# CAL0 register map
Vendor: Texas Instruments
Peripheral module from a debugger description file (folder am65x).
Registers are 32-bit, read-write, reset 0x0 unless marked. A register's access mark holds for its fields unless they carry their own. Offsets are as the file gives them; lines under a group give offsets from that group; [hi:lo] are bit positions; {n}, {i} and the like mark numbered series; 'fields as' and 'values as' point back to an identical list; <NAME> marks a mode.

## CAL0 (part 1 of 2)
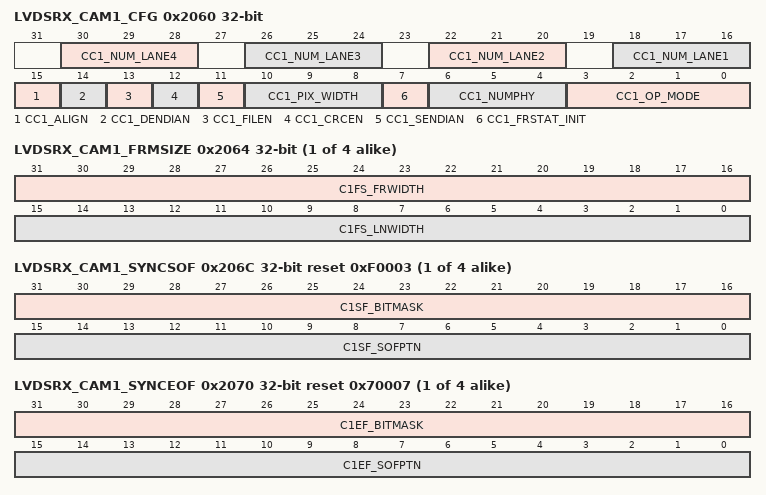
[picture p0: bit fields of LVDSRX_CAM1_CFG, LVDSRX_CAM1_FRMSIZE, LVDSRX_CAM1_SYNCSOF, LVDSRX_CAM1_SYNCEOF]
0x2060 LVDSRX_CAM1_CFG
  [30:28] CC1_NUM_LANE4 — Number of lanes of PHY4 when NUM_PHY&gt;3
  [26:24] CC1_NUM_LANE3 — Number of lanes of PHY3 when NUM_PHY&gt;2
  [22:20] CC1_NUM_LANE2 — Number of lanes of PHY2 when NUM_PHY&gt;1
  [18:16] CC1_NUM_LANE1 — Number of lanes of PHY1
  [15] CC1_ALIGN — MSB, LSB alignment for output pixel data 0: LSB align 1: MSB align
  [14] CC1_DENDIAN — Transmit format of none SYNC area 0: Little endian 1: big endian
  [13] CC1_FILEN — 1: Transmitted data includes filier codes
  [12] CC1_CRCEN — 1: enables checking of the checksum transmitted in the APTINA HiSPi data stream
  [11] CC1_SENDIAN — Transmit format of SYNC area 0: Little endian 1: big endian
  [10:8] CC1_PIX_WIDTH — Word width of recovered parallel data. 0: 8-BITS 1: 10-BITS 2: 12-BITS 3: 14-BITS 4: 16-BITS 5-7: RESERVED
  [7] CC1_FRSTAT_INIT — Specifies Initial frame state in mode2,mode4,mod5 and mode8.If the first comming sync code is knows as start of frame(SOF) when enable decoding, it is able to write 0. If sync code is unknown, should write 1.In other mode, should be coded 0.
  [6:4] CC1_NUMPHY — Number of PHYs 0 ~ 4 is available
  [3:0] CC1_OP_MODE — Protocol selection 0: Serial LVDS mode 1 1: Serial LVDS mode 2 2: Serial LVDS mode 3 3: Serial LVDS mode 4 4: Serial LVDS mode 5 5: Serial LVDS mode 6 6: Serial LVDS mode 7 7: Serial LVDS mode 8 8: Serial LVDS mode 9-15: Reserved
{0x2044+0x20*i} LVDSRX_CAM{i}_FRMSIZE (i=1..4)
  [31:16] C{i}FS_FRWIDTH — Frame size in number of image lines
  [15:0] C{i}FS_LNWIDTH — Image line width in number of data words
{0x2048+0x20*i} LVDSRX_CAM{i}_MAXWIDTH reset 0xFFFF (i=1..4)
  [15:0] C{i}MW_MAXWIDTH — The maximum line width expected in number of pixels.
{0x204C+0x20*i} LVDSRX_CAM{i}_SYNCSOF reset 0xF0003 (i=1..4)
  [31:16] C{i}SF_BITMASK — Specifies the mask bit to be compared. Example: set 0x3ff when doing pattern matching for low 10bit.
  [15:0] C{i}SF_SOFPTN — Specifies SOF(Start Of Frame) sync pattern
{0x2050+0x20*i} LVDSRX_CAM{i}_SYNCEOF reset 0x70007 (i=1..4)
  [31:16] C{i}EF_BITMASK — Specifies the mask bit to be compared. Example: set 0x3ff when doing pattern matching for low 10bit.
  [15:0] C{i}EF_SOFPTN — Specifies SOF(End Of Frame) sync pattern
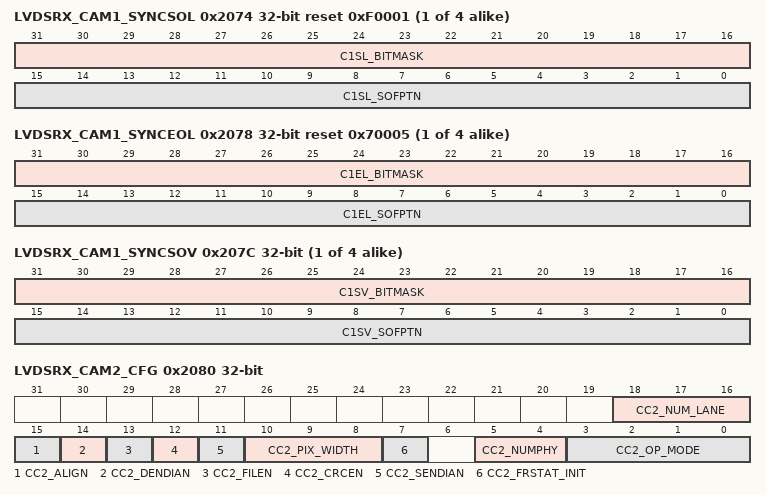
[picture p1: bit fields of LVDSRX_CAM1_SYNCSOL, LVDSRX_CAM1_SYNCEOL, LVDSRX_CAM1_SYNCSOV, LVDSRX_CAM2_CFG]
{0x2054+0x20*i} LVDSRX_CAM{i}_SYNCSOL reset 0xF0001 (i=1..4)
  [31:16] C{i}SL_BITMASK — Specifies the mask bit to be compared. Example: set 0x3ff when doing pattern matching for low 10bit.
  [15:0] C{i}SL_SOFPTN — Specifies SOF(Start Of Line) sync pattern
{0x2058+0x20*i} LVDSRX_CAM{i}_SYNCEOL reset 0x70005 (i=1..4)
  [31:16] C{i}EL_BITMASK — Specifies the mask bit to be compared. Example: set 0x3ff when doing pattern matching for low 10bit.
  [15:0] C{i}EL_SOFPTN — Specifies SOF(End Of Line) sync pattern
{0x205C+0x20*i} LVDSRX_CAM{i}_SYNCSOV (i=1..4)
  [31:16] C{i}SV_BITMASK — Specifies the mask bit to be compared. Example: set 0x3ff when doing pattern matching for low 10bit.
  [15:0] C{i}SV_SOFPTN — Specifies SOF(Start Of V-blanking) sync pattern
0x2080 LVDSRX_CAM2_CFG
  [18:16] CC2_NUM_LANE — Number of lanes of PHY2
  [15] CC2_ALIGN — MSB, LSB alignment for output pixel data 0: LSB align 1: MSB align
  [14] CC2_DENDIAN — Transmit format of none SYNC area 0: Little endian 1: big endian
  [13] CC2_FILEN — 1: Transmitted data includes filier codes
  [12] CC2_CRCEN — 1: enables checking of the checksum transmitted in the APTINA HiSPi data stream
  [11] CC2_SENDIAN — Transmit format of SYNC area 0: Little endian 1: big endian
  [10:8] CC2_PIX_WIDTH — Word width of recovered parallel data. 0: 8-BITS 1: 10-BITS 2: 12-BITS 3: 14-BITS 4: 16-BITS 5-7: RESERVED
  [7] CC2_FRSTAT_INIT — Specifies Initial frame state in mode2, mode4, mod5 and mode8. If the first comming sync code is knows as start of frame(SOF) when enable decoding, it is able to write 0. If sync code is unknown, should write 1. In other mode, should be coded 0.
  [5:4] CC2_NUMPHY — Number of PHYs 0 ~ 1 is available
  [3:0] CC2_OP_MODE — Protocol selection 0: Serial LVDS mode 1 1: Serial LVDS mode 2 2: Serial LVDS mode 3 3: Serial LVDS mode 4 4: Serial LVDS mode 5 5: Serial LVDS mode 6 6: Serial LVDS mode 7 7: Serial LVDS mode 8: Serial LVDS mode 9 9-15: Reserved
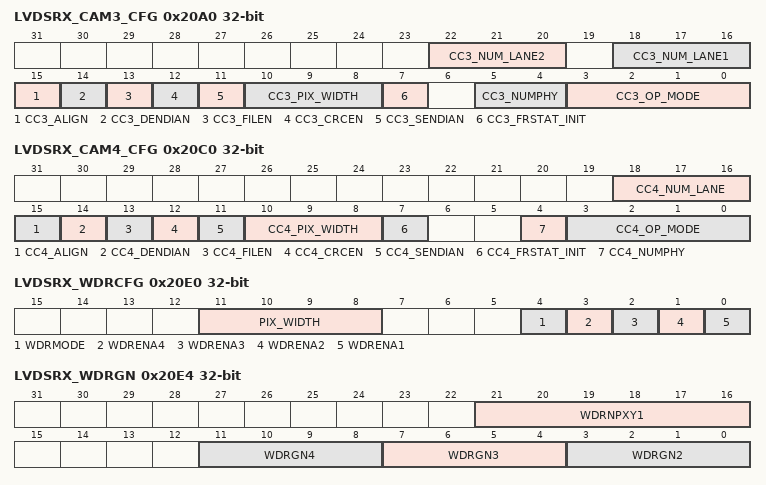
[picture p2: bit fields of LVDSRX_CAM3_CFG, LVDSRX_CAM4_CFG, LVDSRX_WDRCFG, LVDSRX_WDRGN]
0x20A0 LVDSRX_CAM3_CFG
  [22:20] CC3_NUM_LANE2 — Number of lanes of PHY4 when NUM_PHY&gt;1
  [18:16] CC3_NUM_LANE1 — Number of lanes of PHY3
  [15] CC3_ALIGN — MSB, LSB alignment for output pixel data 0: LSB align 1: MSB align
  [14] CC3_DENDIAN — Transmit format of none SYNC area 0: Little endian 1: big endian
  [13] CC3_FILEN — 1: Transmitted data includes filier codes
  [12] CC3_CRCEN — 1: enables checking of the checksum transmitted in the APTINA HiSPi data stream
  [11] CC3_SENDIAN — Transmit format of SYNC area 0: Little endian 1: big endian
  [10:8] CC3_PIX_WIDTH — Word width of recovered parallel data. 0: 8-BITS 1: 10-BITS 2: 12-BITS 3: 14-BITS 4: 16-BITS 5-7: RESERVED
  [7] CC3_FRSTAT_INIT — Specifies Initial frame state in mode2, mode4, mod5 and mode8. If the first comming sync code is knows as start of frame(SOF) when enable decoding, it is able to write 0. If sync code is unknown, should write 1. In other mode, should be coded 0.
  [5:4] CC3_NUMPHY — Number of PHYs 0,1, 2 is available
  [3:0] CC3_OP_MODE — Protocol selection 0: Serial LVDS mode 1 1: Serial LVDS mode 2 2: Serial LVDS mode 3 3: Serial LVDS mode 4 4: Serial LVDS mode 5 5: Serial LVDS mode 6 6: Serial LVDS mode 7 7: Serial LVDS mode 8: Serial LVDS mode 9 9-15: Reserved
0x20C0 LVDSRX_CAM4_CFG
  [18:16] CC4_NUM_LANE — Number of lanes of PHY4
  [15] CC4_ALIGN — MSB, LSB alignment for output pixel data 0: LSB align 1: MSB align
  [14] CC4_DENDIAN — Transmit format of none SYNC area 0: Little endian 1: big endian
  [13] CC4_FILEN — 1: Transmitted data includes filier codes
  [12] CC4_CRCEN — 1: enables checking of the checksum transmitted in the APTINA HiSPi data stream
  [11] CC4_SENDIAN — Transmit format of SYNC area 0: Little endian 1: big endian
  [10:8] CC4_PIX_WIDTH — Word width of recovered parallel data. 0: 8-BITS 1: 10-BITS 2: 12-BITS 3: 14-BITS 4: 16-BITS 5-7: RESERVED
  [7] CC4_FRSTAT_INIT — Specifies Initial frame state in mode2, mode4, mod5 and mode8. If the first comming sync code is knows as start of frame(SOF) when enable decoding, it is able to write 0. If sync code is unknown, should write 1. In other mode, should be coded 0.
  [4] CC4_NUMPHY — Number of PHYs 0,1 is available
  [3:0] CC4_OP_MODE — Protocol selection 0: Serial LVDS mode 1 1: Serial LVDS mode 2 2: Serial LVDS mode 3 3: Serial LVDS mode 4 4: Serial LVDS mode 5 5: Serial LVDS mode 6 6: Serial LVDS mode 7: Serial LVDS mode 8: Serial LVDS mode 9 9-13: Reserved 14: CMOS parallel IF (CCIR656 embeded sync) 15: CMOS parallel IF (extenal HSYNC/VSYNC). When in mode 14,15, the input parallel i/f signals go to CAM #4 output port.
0x20E0 LVDSRX_WDRCFG
  [11:8] PIX_WIDTH — Word width after de-companded. 0: 12-BITS 1: 13-BITS 2: 14-BITS 3: 15-BITS 4: 16-BITS 5: 17-BITS 6: 18-BITS 7: 19-BITS 8: 20-BITS 9-15: RESERVED
  [4] WDRMODE — WDR mode select 0: de-companding 1: bit interlaced format. Not allowed to code 1 to WDRENA3 and WDRENA4 at the same time.
  [3] WDRENA4 — WDR mode enable for CAM port #4. 0: disable 1: enable WDR function. Not allowed to code 1 to WDRENA3 and WDRENA4 at the same time.
  [2] WDRENA3 — WDR mode enable for CAM port #3. 0: disable 1: enable WDR function. Not allowed to code 1 to WDRENA3 and WDRENA4 at the same time.
  [1] WDRENA2 — WDR mode enable for CAM port #2. 0: disable 1: enable WDR function. Not allowed to code 1 to WDRENA1 and WDRENA2 at the same time.
  [0] WDRENA1 — WDR mode enable for CAM port #1. 0: disable 1: enable WDR function. Not allowed to code 1 to WDRENA1 and WDRENA2 at the same time.
0x20E4 LVDSRX_WDRGN
  [21:16] WDRNPXY1 — Specifies the pixel level for area #1 knee point in X/Y axis. Level = WDRNPXY1 * 256.
  [11:8] WDRGN4 — Specifies the gain for area #4. Gain = 1/2WDRGN4.
  [7:4] WDRGN3 — Specifies the gain for area #3. Gain = 1/2WDRGN3.
  [3:0] WDRGN2 — Specifies the gain for area #2. Gain = 1/2WDRGN2.
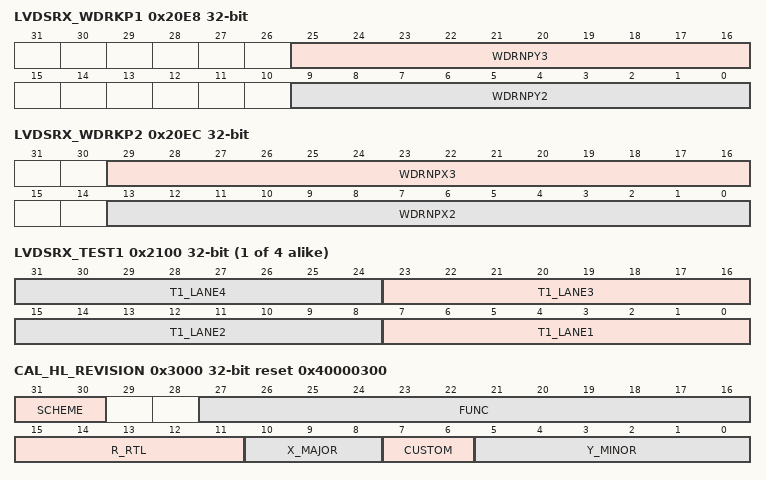
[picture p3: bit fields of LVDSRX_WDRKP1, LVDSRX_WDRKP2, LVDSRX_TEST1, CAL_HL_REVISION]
0x20E8 LVDSRX_WDRKP1
  [25:16] WDRNPY3 — Specifies the pixel level for area #3 knee point in Y axis. Level = WDRNPY3 * 256.
  [9:0] WDRNPY2 — Specifies the pixel level for area #2 knee point in Y axis. Level = WDRNPY2 * 256.
0x20EC LVDSRX_WDRKP2
  [29:16] WDRNPX3 — Specifies the pixel level for area #3 knee point in X axis. Level = WDRNPX3.
  [13:0] WDRNPX2 — Specifies the pixel level for area #2 knee point in X axis. Level = WDRNPX2.
{0x20FC+4i} LVDSRX_TEST{i} ro (i=1..4)
  [8n-1:8n-8] T{i}_LANE{n} (n=1..4) — lane #{n} byte data
0x3000 CAL_HL_REVISION ro reset 0x40000300 — IP Revision Identifier (X.Y.R) Used by software to track features, bugs, and compatibility
  [31:30] SCHEME — Used to distinguish between old scheme and current.
  [27:16] FUNC — Function indicates a software compatible module family. If there is no level of software compatibility a new Func number (and hence CAL_REVISION) should be assigned.
  [15:11] R_RTL — RTL Version (R), maintained by IP design owner. RTL follows a numbering such as X.Y.R.Z which are explained in this table. R changes ONLY when: (1) PDS uploads occur which may have been due to spec changes (2) Bug fixes occur (3) Resets to '0' when X or Y changes. Design team has an internal 'Z' (customer invisible) number which increments on every drop that happens due to DV and RTL updates. Z resets to 0 when R increments.
  [10:8] X_MAJOR — Major Revision (X), maintained by IP specification owner. X changes ONLY when: (1) There is a major feature addition. An example would be adding Master Mode to Utopia Level2. The Func field (or Class/Type in old CAL_PID format) will remain the same. X does NOT change due to: (1) Bug fixes (2) Change in feature parameters.
  [7:6] CUSTOM — Indicates a special version for a particular device. Consequence of use may avoid use of standard Chip Support Library (CSL) / Drivers.
  [5:0] Y_MINOR — Minor Revision (Y), maintained by IP specification owner. Y changes ONLY when: (1) Features are scaled (up or down). Flexibility exists in that this feature scalability may either be represented in the Y change or a specific register in the IP that indicates which features are exactly available. (2) When feature creeps from Is-Not list to Is list. But this may not be the case once it sees silicon in which case X will change. Y does NOT change due to: (1) Bug fixes (2) Typos or clarifications (3) major functional/feature change/addition/deletion. Instead these changes may be reflected via R, S, X as applicable. Spec owner maintains a customer-invisible number 'S' which changes due to: (1) Typos/clarifications (2) Bug documentation. Note that this bug is not due to a spec change but due to implementation. Nevertheless, the spec tracks the IP bugs. An RTL release (say for silicon PG1.1) that occurs due to bug fix should
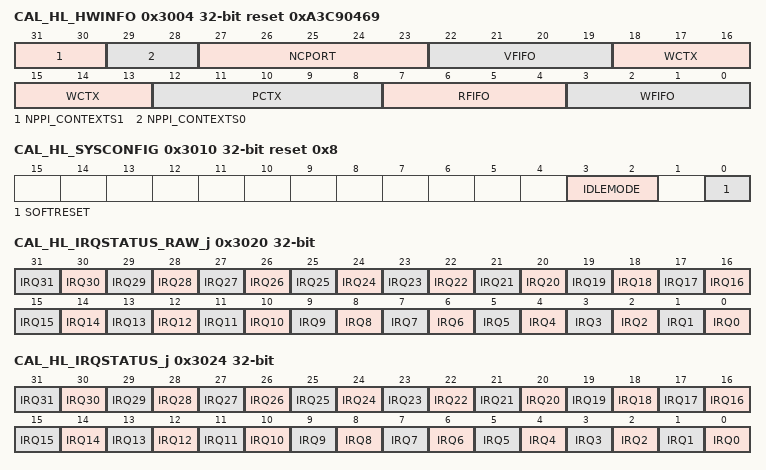
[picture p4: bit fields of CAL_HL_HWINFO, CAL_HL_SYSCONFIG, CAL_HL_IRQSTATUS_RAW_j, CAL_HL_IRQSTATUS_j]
0x3004 CAL_HL_HWINFO ro reset 0xA3C90469 — Information about the IP module's hardware configuration, i.e. typically the module's HDL generics (if any). Actual field format and encoding is up to the module's designer to decide.
  [31:30] NPPI_CONTEXTS1 — Number of contexts for PPI interface #1
  [29:28] NPPI_CONTEXTS0 — Number of contexts for PPI interface #0
  [27:23] NCPORT — Number of supported CPORTs (including CPORT #0) minus 1. That number typically corresponds to the number of CPORTs that can provide data from OCPI. Example: NCPORT = 7 means that CAL implements 8 CPorts but one of them (CPORT0) is typically used for data read from memory and typically 7 CPorts (CPORT1 ~ CPORT7) can be used for data received on OCPI. Note: Equals NCPORT generic parameter minus 1
  [22:19] VFIFO — Video port FIFO size
  [18:13] WCTX — Number of implemented DMA write contexts
  [12:8] PCTX — Number of implemented pixel processing contexts
  [7:4] RFIFO — Read FIFO size 2^RFIFO words of 16 bytes
  [3:0] WFIFO — Write FIFO size 2^WFIFO words of 16 bytes
0x3010 CAL_HL_SYSCONFIG reset 0x8 — Clock management configuration
  [3:2] IDLEMODE — IDLE protocol configuration
  [0] SOFTRESET — Software reset
0x301C CAL_HL_IRQ_EOI — End Of Interrupt number specification The EOI register is used to re-trigger the pulse interrupt signal to ensure that any nested interrupt events are serviced. The software interrupt handler must write to the EOI register at the end of the current interrupt processing routine, so that new events can re-trigger the pulse interrupt signal again. For level interrupt signals the EOI register is not functional and must not be used.
  [0] LINE_NUMBER — Software End Of Interrupt (EOI) control. Write number of interrupt output.
0x3020 CAL_HL_IRQSTATUS_RAW_j access not given — Per-event raw interrupt status vector, line #0. Raw status is set even if event is not enabled. Offset = 3020h + (j * 10h); where j = 0h to 7h
  [n] IRQ{n} (n=0..31) — For details, check section CAL Interrupt Events. (access RW1S)
0x3024 CAL_HL_IRQSTATUS_j access not given — Per-event enabled interrupt status vector, line #0. Enabled status isn't set unless event is enabled. Offset = 3024h + (j * 10h); where j = 0h to 7h
  [n] IRQ{n} (n=0..31) — For details, check section CAL Interrupt Events. (access RW1C)
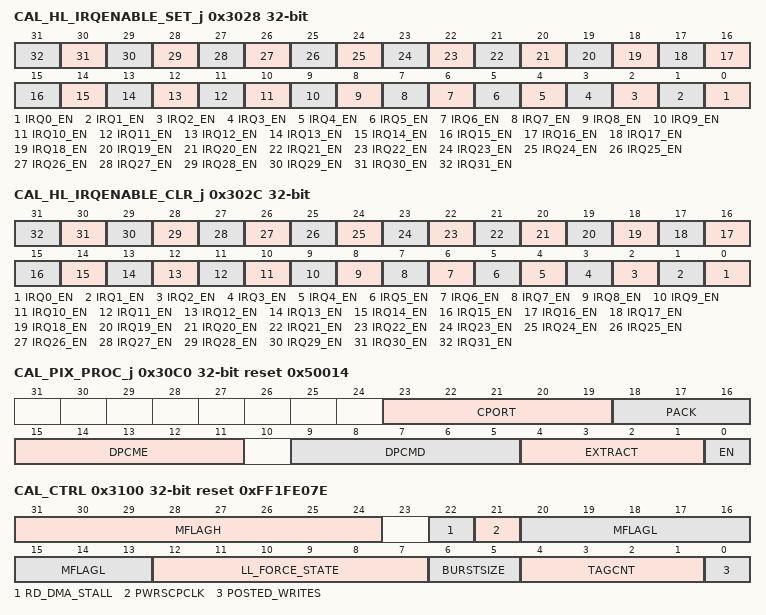
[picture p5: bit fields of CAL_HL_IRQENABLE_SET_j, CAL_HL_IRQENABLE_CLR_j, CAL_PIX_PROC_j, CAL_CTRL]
0x3028 CAL_HL_IRQENABLE_SET_j access not given — Per-event interrupt enable bit vector Write 1 to set (enable interrupt). Readout equal to corresponding _CLR register. Offset = 3028h + (j * 10h); where j = 0h to 7h
  [n] IRQ{n}_EN (n=0..31) — For details, check section CAL Interrupt Events. (access RW1S)
0x302C CAL_HL_IRQENABLE_CLR_j access not given — Per-event interrupt enable bit vector Write 1 to clear (disable interrupt). Readout equal to corresponding _SET register. Offset = 302Ch + (j * 10h); where j = 0h to 7h
  [n] IRQ{n}_EN (n=0..31) — For details, check section CAL Interrupt Events. (access RW1C)
0x30C0 CAL_PIX_PROC_j reset 0x50014 — Pixel processing control Offset = 30C0h + (j * 4h); where j = 0h to 3h
  [23:19] CPORT — CPort ID to process.
  [18:16] PACK — Control pixel packing
  [15:11] DPCME — DPCM encoder
  [9:5] DPCMD — DPCM Decoder
  [4:1] EXTRACT — Control pixel extraction from the byte stream
  [0] EN — Enable the pixel processing context
0x3100 CAL_CTRL access per field reset 0xFF1FE07E — Global control register
  [31:24] MFLAGH rw — Refer to section CAL Write DMA Real Time Traffic.
  [22] RD_DMA_STALL rw — Controls if the pixel stream from the RD DMA's FIFO to the internal pipeline shall be stalled when MFlag/=0. Shall be enabled to protect real time traffic against non real time, memory to memory dataflows through CAL.
  [21] PWRSCPCLK rw — Controls autogating of the PWRSCP clock
  [20:13] MFLAGL rw — Refer to section CAL Write DMA Real Time Traffic.
  [12:7] LL_FORCE_STATE wo — Forces the state of the CSI-3 low level protocol state machine. Intended to recover synchronization. Writing 0 into this register has no effect. Reads always return 0s bit 0: 0: the next OCPI transaction for this CPORT will only contain data 1: the next OCPI transaction for this CPORT will contain the CSI-3 packet header bit 1~5: CPort ID (1..31)
  [6:5] BURSTSIZE rw — Maximum allowed burst size for the write DMA.
  [4:1] TAGCNT rw — Maximum number of outstanding OCP transactions = TAGCNT+1
  [0] POSTED_WRITES rw
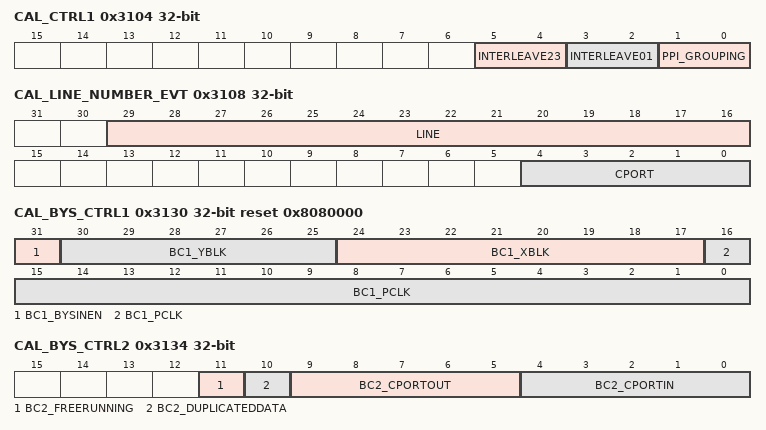
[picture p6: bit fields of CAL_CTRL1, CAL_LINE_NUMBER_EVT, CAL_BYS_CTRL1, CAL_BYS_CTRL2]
0x3104 CAL_CTRL1 — CAL global control register
  [5:4] INTERLEAVE23 — Controls stream interleaving Context #2 and #3
  [3:2] INTERLEAVE01 — Controls stream interleaving Context #0 and #1
  [1:0] PPI_GROUPING — Controls PPI grouping
0x3108 CAL_LINE_NUMBER_EVT — Controls generation of the line number event
  [29:16] LINE — 0: Event triggered when PIX_DAT_FS TAG is received by the line number event generator 1 ~ 2^14-1: Event triggered when the LINEth occurece of the PIX_DAT_LS TAG is received by the line number event generator.
  [4:0] CPORT — CPort ID to monitor
0x3130 CAL_BYS_CTRL1 reset 0x8080000 — BYS port control register
  [31] BC1_BYSINEN — Enable/disable the BYS input port.
  [30:25] BC1_YBLK — Vertical blanking = YBLK lines. Valid range: 0 ... 63.
  [24:17] BC1_XBLK — Horizontal blanking = 8*XBLK cycles. Valid range = 0..2040 cycles.
  [16:0] BC1_PCLK — BYSout port pixel clock = FCLK * PCLK / 2^16. Valid range: 0 .. 2^16. 0 disables the BYS output port.
0x3134 CAL_BYS_CTRL2 — BYS port control register
  [11] BC2_FREERUNNING — Controls PCLK generation when the BYSout state machine is in the IDLE state
  [10] BC2_DUPLICATEDDATA — Control if data sent to the BYS output port should also be send to the DPCM encoder
  [9:5] BC2_CPORTOUT — BYS output port processes data received with the CPORT ID defined in this register
  [4:0] BC2_CPORTIN — Cport ID used for data received from the BYSin port
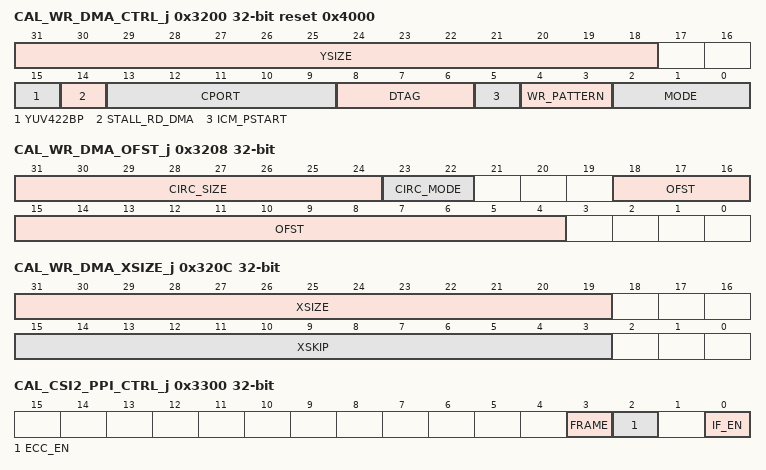
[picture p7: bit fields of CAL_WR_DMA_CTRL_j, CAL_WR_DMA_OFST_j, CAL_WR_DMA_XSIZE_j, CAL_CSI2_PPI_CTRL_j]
0x3200 CAL_WR_DMA_CTRL_j reset 0x4000 — Write DMA control register Offset = 3200h + (j * 10h); where j = 0h to 7h
  [31:18] YSIZE — Maximum number of lines the WR DMA can write to memory. That feature is typically used to prevent writes outside of an allocated memory buffer (may, for example, happen when sync information is lost). 0: No limitation. All received lines are written to memory. 1 ~ 2^14-1: maximum number of lines to write to memory
  [15] YUV422BP — Activates YUV422BP conversation (from YUV422). Requires two consecutive WrDMA channels where first channel is even and second is odd. Both channels shall be programmed identically except for DMA destination address. 0 - DISABLED - normal, no conversion. 1 - ENABLED - conversion enabled. Only supported, if CALSS_MODE[0] BASELINE_MODE register bit is '0'.
  [14] STALL_RD_DMA — Controls if a the RD DMA shall be stalled when the write context is stalled because it waits for the PSTART pulse. 0 - DISABLED, Don't stall the read DMA 1 - ENABLE, Stall the read DMA if the write DMA context is stalled.
  [13:9] CPORT — Cport ID
  [8:6] DTAG — Store data tagged as DTAG 0x0 - ATT_HDR, Attribute packet headers. TAG=ATT_HDR_S, ATT_HDR_E 0x1 - ATT_DAT, Attribute data. TAG=ATT_DAT_S, ATT_DAT, ATT_DAT_E 0x2 - CAL_CTRL, Control packets. TAG=CTRL_HDR_S, CTRL_HDR_E 0x3 - PIX_HDR, Pixel packet headers. TAG=PIX_HDR_S, PIX_HDR_E 0x4 - PIX_DAT, Pixel data. TAG=PIX_DAT_FS, PIX_DAT_LS, PIX_DAT, PIX_DAT_LE, PIX_DAT_FE, FE_CODE 0x5 - D5, reserved 0x6 - D6, reserved 0x7 - D7, reserved
  [5] ICM_PSTART — Enables monitoring of the ICM_PSTART[x] signal. 0 - Disabled. Ignore PSTART input. 1 - Enabled. Write the number of lines defined by CAL_WR_DMA_OFST_j.CIRC_MODE for each received PSTART pulse.
  [4:3] WR_PATTERN — Data write pattern
  [2:0] MODE — Mode 0x0 - DIS - Disable 0x1 - SHD - Ping/pong destination address on every frame 0x2 - CNT - Continously write data to memory 0x3 - CNT_INIT - Initialize start address for continous mode. The 1st frame will be written at this address and consecutive frames will be appended. 0x4 - CONST - Use CAL_WR_DMA_ADDR_j as base address. 0x5 - 0x7 - Reserved
0x3204 CAL_WR_DMA_ADDR_j — Byte address of the top left corner of the buffer to write in system memory Offset = 3204h + (j * 10h); where j = 0h to 7h
  [31:4] ADDR — Destination address, in words of 16 bytes. This value should be a multiple of 128 bytes for best performance.
0x3208 CAL_WR_DMA_OFST_j — Offset between two consecutive line starts. Signed value. SW can directly write a signed 32-bit offset into that register. Valid range = -262144 .. 262143 Offset = 3208h + (j * 10h); where j = 0h to 7h
  [31:24] CIRC_SIZE — Circular buffer size minus one. Unit defined by the CIRC_MODE register. Example: Circular buffer size = 16k lines when CIRC_SIZE=255 and CIRC_MODE=3
  [23:22] CIRC_MODE — Defines the granularity for circular buffer mode. Circular adressing mode shall be disabled (CIRC_MODE=0) when CAL_WR_DMA_CTRL_j.MODE bit isn't CONST. 0x0 - DISABLED, Circular addressing mode disabled 0x1 - ONE, 1 Line 0x2 - FOUR, 4 lines 0x3 - SIXTYFOUR, 64 lines
  [18:4] OFST — Offset in words of 16 bytes.
0x320C CAL_WR_DMA_XSIZE_j — Defines the size of a line written to memory. The minimum size to be written must be >= 16 bytes. Offset = 320Ch + (j * 10h); where j = 0h to 7h
  [31:19] XSIZE — Words of 64-bits to write per line. Valid range = 0 or 1..n 0 : write the complete stream until the end is detected. n = stream size in words of 64 bits
  [15:3] XSKIP — Words of 64 bits to skip from the line start. Valid range: 0...n-1 n = number or 64-bit words in the stream
0x3300 CAL_CSI2_PPI_CTRL_j — Controls the low level CSI-2 protocol interface (PPI) Offset = 3300h + (j * 80h); where j = 0h to 1h
  [3] FRAME — Set the modality in which IF_EN works.
  [2] ECC_EN — Enables the Error Correction Code check for the received header (short and long packets for all virtual channel IDs).
  [0] IF_EN — Enables the physical interface to the module.
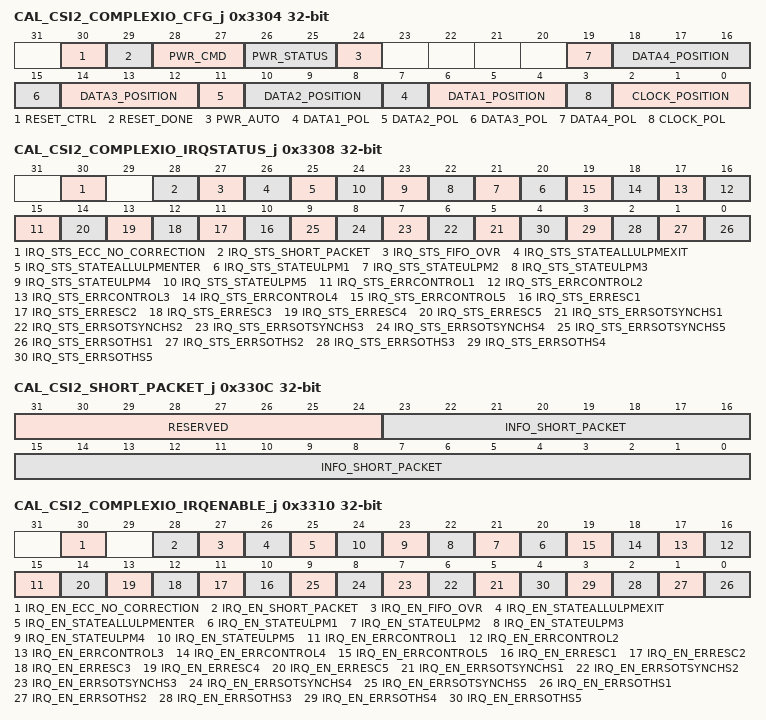
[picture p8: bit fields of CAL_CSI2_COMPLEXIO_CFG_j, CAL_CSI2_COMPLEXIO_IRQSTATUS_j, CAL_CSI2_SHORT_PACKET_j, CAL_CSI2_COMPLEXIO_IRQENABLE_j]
0x3304 CAL_CSI2_COMPLEXIO_CFG_j access per field — COMPLEXIO CONFIGURATION REGISTER This register contains the lane configuration for the order and position of the lanes (clock and data) and the polarity order for the control of the PHY differential signals in addition to the control bit for the power FSM. Offset = 3304h + (j * 80h); where j = 0h to 1h
  [30] RESET_CTRL rw — Controls the reset of the complex IO
  [29] RESET_DONE ro — Internal reset monitoring of the power domain using the PPI byte clock from the complex IO
  [28:27] PWR_CMD rw — Command for power control of the complex IO
  [26:25] PWR_STATUS ro — Status of the power control of the complex IO
  [24] PWR_AUTO rw — Automatic switch between ULP and ON states based on ULPM signals from complex iO
  [4n+3] DATA{n}_POL rw (n=1..4) — +/- differential pin order of DATA lane {n}.
  [18:16] DATA4_POSITION rw — Position and order of the DATA lane 4. The values 6 and 7 are reserved.
  [14:12] DATA3_POSITION rw — Position and order of the DATA lane 3. The values 6 and 7 are reserved.
  [10:8] DATA2_POSITION rw — Position and order of the DATA lane 2. The values 6 and 7 are reserved.
  [6:4] DATA1_POSITION rw — Position and order of the DATA lane 1. 0, 6 and 7 are reserved. The data lane 1 is always present.
  [3] CLOCK_POL rw — +/- differential pin order of CLOCK lane.
  [2:0] CLOCK_POSITION rw — Position and order of the CLOCK lane. 0, 6 and 7 are reserved. The clock lane is always present.
0x3308 CAL_CSI2_COMPLEXIO_IRQSTATUS_j — INTERRUPT STATUS REGISTER - All errors from complex IO #1 Offset = 3308h + (j * 80h); where j = 0h to 1h
  [30] IRQ_STS_ECC_NO_CORRECTION — ECC has not been used to correct the header because there is more than 1-bit error (short and long packets).
  [28] IRQ_STS_SHORT_PACKET — Short packet (other than FS, FE, LS, LE) received.
  [27] IRQ_STS_FIFO_OVR — CSI-2 low level protocol interface FIFO overflow
  [26] IRQ_STS_STATEALLULPMEXIT — At least one of the active lanes has exit the ULPM
  [25] IRQ_STS_STATEALLULPMENTER — All active lanes are entering in ULPM.
  [n+19] IRQ_STS_STATEULPM{n} (n=1..5) — Lane #{n} in Ultra Low Power Mode
  [n+14] IRQ_STS_ERRCONTROL{n} (n=1..5) — Control error for lane #{n}
  [n+9] IRQ_STS_ERRESC{n} (n=1..5) — Escape entry error for lane #{n}
  [n+4] IRQ_STS_ERRSOTSYNCHS{n} (n=1..5) — Start of transmission sync error for lane #{n}
  [n-1] IRQ_STS_ERRSOTHS{n} (n=1..5) — Start of transmission error for lane #{n}
0x330C CAL_CSI2_SHORT_PACKET_j ro — SHORT PACKET INFORMATION - This register sets the 24-bit DATA_ID + Short Packet Data Field when the data type is between 0x8 and x0F Offset = 330Ch + (j * 80h); where j = 0h to 1h
  [31:24] RESERVED — Reads returns 0.
  [23:0] INFO_SHORT_PACKET — Short Packet information: DATA ID + DATA FIELD
0x3310 CAL_CSI2_COMPLEXIO_IRQENABLE_j — INTERRUPT ENABLE REGISTER - All errors from complex IO #1 Offset = 3310h + (j * 80h); where j = 0h to 1h
  [30] IRQ_EN_ECC_NO_CORRECTION — ECC has not been used to correct the header because there is more than 1-bit error (short and long packets).
  [28] IRQ_EN_SHORT_PACKET — Short packet (other than FS, FE, LS, LE) received.
  [27] IRQ_EN_FIFO_OVR — CSI-2 low level protocol interface FIFO overflow
  [26] IRQ_EN_STATEALLULPMEXIT — At least one of the active lanes has exit the ULPM
  [25] IRQ_EN_STATEALLULPMENTER — All active lanes are entering in ULPM.
  [n+19] IRQ_EN_STATEULPM{n} (n=1..5) — Lane #{n} in Ultra Low Power Mode
  [n+14] IRQ_EN_ERRCONTROL{n} (n=1..5) — Control error for lane #{n}
  [n+9] IRQ_EN_ERRESC{n} (n=1..5) — Escape entry error for lane #{n}
  [n+4] IRQ_EN_ERRSOTSYNCHS{n} (n=1..5) — Start of transmission sync error for lane #{n}
  [n-1] IRQ_EN_ERRSOTHS{n} (n=1..5) — Start of transmission error for lane #{n}
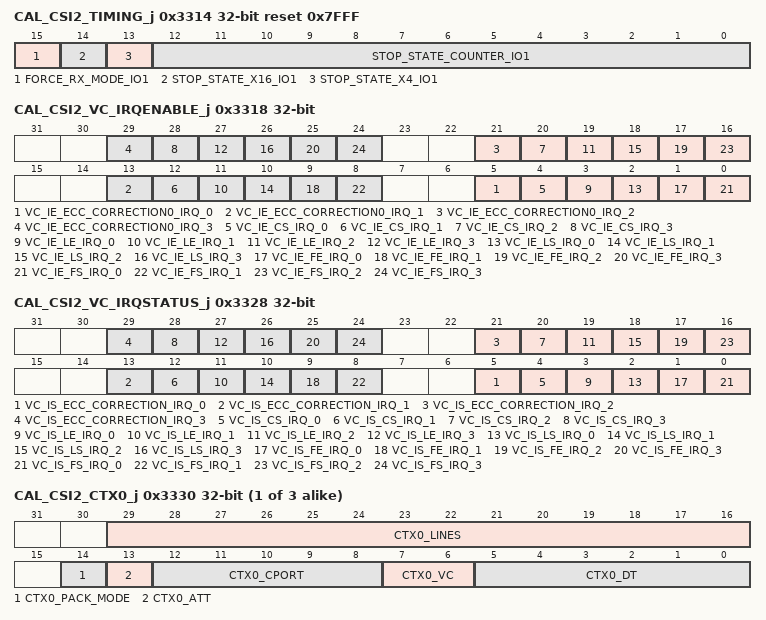
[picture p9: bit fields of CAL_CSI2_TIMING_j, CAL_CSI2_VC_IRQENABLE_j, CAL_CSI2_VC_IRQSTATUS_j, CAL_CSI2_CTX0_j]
0x3314 CAL_CSI2_TIMING_j reset 0x7FFF — TIMING REGISTER This register shall not be =modified when CAL_CSI2_PPI_CTRL.IF_EN=1 It is used to indicate the number of functional clock cycles for the Stop State monitoring. Offset = 3314h + (j * 80h); where j = 0h to 1h
  [15] FORCE_RX_MODE_IO1 — Control of ForceRxMode signal
  [14] STOP_STATE_X16_IO1 — Multiplication factor for the number of L3 cycles defined in STOP_STATE_COUNTER bit-field
  [13] STOP_STATE_X4_IO1 — Multiplication factor for the number of L3 cycles defined in STOP_STATE_COUNTER bit-field
  [12:0] STOP_STATE_COUNTER_IO1 — Stop State counter for monitoring. It indicates the number of L3 to monitor for Stop State before de-asserting ForceRxMode (Complex IO #1). The value is from 0 to 8191.
0x3318 CAL_CSI2_VC_IRQENABLE_j — INTERRUPT ENABLE REGISTER - Virtual channels Offset = 3318h + (j * 80h); where j = 0h to 1h
  [8n+5] VC_IE_ECC_CORRECTION0_IRQ_{n} (n=0..3) — ECC has been used to correct the only 1-bit error
  [8n+4] VC_IE_CS_IRQ_{n} (n=0..3) — Check-Sum of the payload mismatch detection
  [8n+3] VC_IE_LE_IRQ_{n} (n=0..3) — Line end sync code detection.
  [8n+2] VC_IE_LS_IRQ_{n} (n=0..3) — Line start sync code detection.
  [8n+1] VC_IE_FE_IRQ_{n} (n=0..3) — Frame end sync code detection.
  [8n] VC_IE_FS_IRQ_{n} (n=0..3) — Frame start sync code detection.
0x3328 CAL_CSI2_VC_IRQSTATUS_j — INTERRUPT STATUS REGISTER - Virtual channels This register regroups all the events related to Context. Offset = 3328h + (j * 80h); where j = 0h to 1h
  [8n+5] VC_IS_ECC_CORRECTION_IRQ_{n} (n=0..3) — ECC has been used to do the correction of the only 1-bit error status
  [8n+4] VC_IS_CS_IRQ_{n} (n=0..3) — Check-Sum mismatch status.
  [8n+3] VC_IS_LE_IRQ_{n} (n=0..3) — Line end sync code detection status.
  [8n+2] VC_IS_LS_IRQ_{n} (n=0..3) — Line start sync code detection status.
  [8n+1] VC_IS_FE_IRQ_{n} (n=0..3) — Frame end sync code detection status.
  [8n] VC_IS_FS_IRQ_{n} (n=0..3) — Frame start sync code detection status.
{0x3330+4i} CAL_CSI2_CTX{i}_j (i=0..2) — Context control Offset = {4i+3330}h + (j * 80h); where j = 0h to 1h
  [29:16] CTX{i}_LINES — Number of expected lines 0: Number of lines unknown. TAG generation FSM will insert a dummy line upon reception of a FE short packet. &gt;0: Number of lines
  [14] CTX{i}_PACK_MODE — Controls the data packing behavior
  [13] CTX{i}_ATT — Selects which tags to use for the CAL internal pipeline
  [12:8] CTX{i}_CPORT — CAL internal CPort ID to use for Data
  [7:6] CTX{i}_VC — Virtual channel
  [5:0] CTX{i}_DT — DT value received over CSI-2 to use for data. 0x00 : context is disabled (don't receive data) 0x01 : filter is disabled (accept any DT) 0x02 ~ 0x0F: reserved 0x10 ~ 0x3F: receive data with Data Type field = DT
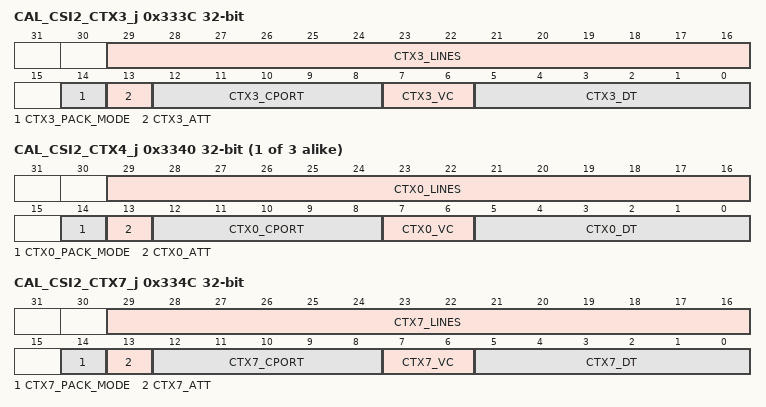
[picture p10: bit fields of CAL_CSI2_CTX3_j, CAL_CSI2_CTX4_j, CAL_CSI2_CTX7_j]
0x333C CAL_CSI2_CTX3_j — Context control Offset = 333Ch + (j * 80h); where j = 0h to 1h
  [29:16] CTX3_LINES — Number of expected lines 0: Number of lines unknown. TAG generation FSM will insert a dummy line upon reception of a FE short packet. &gt;0: Number of lines
  [14] CTX3_PACK_MODE — Controls the data packing behavior
  [13] CTX3_ATT — Selects which tags to use for the CAL internal pipeline
  [12:8] CTX3_CPORT — CAL internal CPort ID to use for Data
  [7:6] CTX3_VC — Virtual channel
  [5:0] CTX3_DT — DT value received over CSI-2 to use for data. 0x00 : context is disabled (don't receive data) 0x01 : filter is disabled (accept any DT) 0x02 ~ 0x0F: reserved 0x10 ~ 0x3F: receive data with Data Type field = DT
{0x3330+4i} CAL_CSI2_CTX{i}_j (i=4..6) — Context control Offset = {4i+3324}h + (j * 80h); where j = 0h to 1h
  fields as CAL_CSI2_CTX0_j
0x334C CAL_CSI2_CTX7_j — Context control Offset = 334Ch + (j * 80h); where j = 0h to 1h
  [29:16] CTX7_LINES — Number of expected lines 0: Number of lines unknown. TAG generation FSM will insert a dummy line upon reception of a FE short packet. &gt;0: Number of lines
  [14] CTX7_PACK_MODE — Controls the data packing behavior
  [13] CTX7_ATT — Selects which tags to use for the CAL internal pipeline
  [12:8] CTX7_CPORT — CAL internal CPort ID to use for Data
  [7:6] CTX7_VC — Virtual channel
  [5:0] CTX7_DT — DT value received over CSI-2 to use for data. 0x00 : context is disabled (don't receive data) 0x01 : filter is disabled (accept any DT) 0x02 ~ 0x0F: reserved 0x10 ~ 0x3F: receive data with Data Type field = DT
{0x3350+4i} CAL_CSI2_STATUS{i}_j ro (i=0..2) — Context status register Offset = {4i+3350}h + (j * 80h); where j = 0h to 1h
  [15:0] STS{i}_FRAME — Frame number. Matches the frame number sent by the camera when the camera transmits it. Otherwise, incremented by one on every FS short packet for this context. Reset when the context is enabled.
0x335C CAL_CSI2_STATUS3_j ro — Context status register Offset = 335Ch + (j * 80h); where j = 0h to 1h
  [15:0] STS3_FRAME — Frame number. Matches the frame number sent by the camera when the camera transmits it. Otherwise, incremented by one on every FS short packet for this context. Reset when the context is enabled.
{0x3350+4i} CAL_CSI2_STATUS{i}_j ro (i=4..6) — Context status register Offset = {4i+3344}h + (j * 80h); where j = 0h to 1h
  fields as CAL_CSI2_STATUS0_j
0x336C CAL_CSI2_STATUS7_j ro — Context status register Offset = 336Ch + (j * 80h); where j = 0h to 1h
  [15:0] STS7_FRAME — Frame number. Matches the frame number sent by the camera when the camera transmits it. Otherwise, incremented by one on every FS short packet for this context. Reset when the context is enabled.
